# RX64M_RTC_Pilot register map
File version: 1.0
RX64M_RTC_Pilot peripheral registers generated from iodefine.h (pilot).
Registers are 8-bit, read-write, no defined reset value unless marked. A register's access mark holds for its fields unless they carry their own. Offsets are from the block's base; lines under a group give offsets from that group; [hi:lo] are bit positions; {n}, {i} and the like mark numbered series; 'fields as' and 'values as' point back to an identical list; <NAME> marks a mode.

## Memory map
0x0008C400 RTC size 0x7D

## RTC
Base 0x0008C400
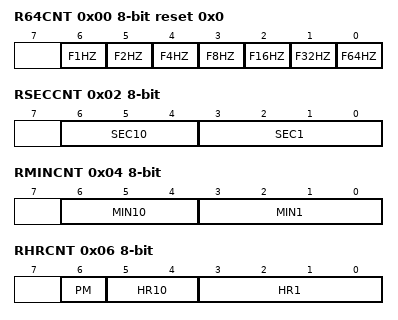
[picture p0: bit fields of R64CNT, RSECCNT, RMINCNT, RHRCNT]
0x00 R64CNT ro reset 0x0 (reset mask 0x80)
  [6] F1HZ, [5] F2HZ, [4] F4HZ, [3] F8HZ, [2] F16HZ, [1] F32HZ, [0] F64HZ
0x02 RSECCNT
  [6:4] SEC10, [3:0] SEC1
0x02 BCNT0 (alternate view of RSECCNT)
  [7:0] BCNT
0x04 RMINCNT
  [6:4] MIN10, [3:0] MIN1
0x04 BCNT1 (alternate view of RMINCNT)
  [7:0] BCNT
0x06 RHRCNT
  [6] PM, [5:4] HR10, [3:0] HR1
0x06 BCNT2 (alternate view of RHRCNT)
  [7:0] BCNT
0x08 RWKCNT
  [2:0] DAYW
0x08 BCNT3 (alternate view of RWKCNT)
  [7:0] BCNT
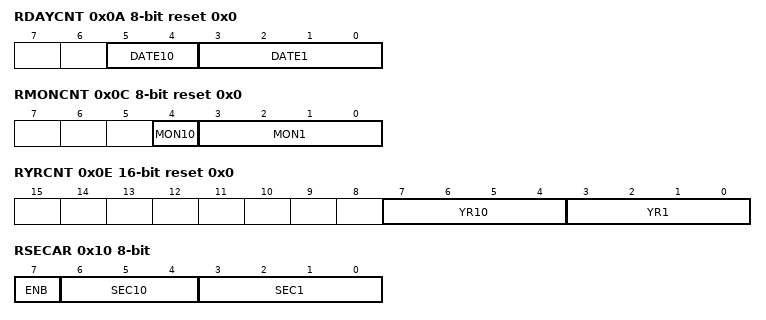
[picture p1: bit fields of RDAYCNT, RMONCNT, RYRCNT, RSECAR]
0x0A RDAYCNT reset 0x0 (reset mask 0xC0)
  [5:4] DATE10, [3:0] DATE1
0x0C RMONCNT reset 0x0 (reset mask 0xE0)
  [4] MON10, [3:0] MON1
0x0E RYRCNT 16-bit reset 0x0 (reset mask 0xFF00)
  [7:4] YR10, [3:0] YR1
0x10 RSECAR
  [7] ENB, [6:4] SEC10, [3:0] SEC1
0x10 BCNT0AR (alternate view of RSECAR)
  [7:0] BCNTAR
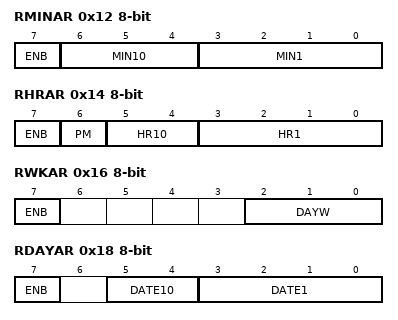
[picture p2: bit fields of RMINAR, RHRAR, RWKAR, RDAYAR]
0x12 RMINAR
  [7] ENB, [6:4] MIN10, [3:0] MIN1
0x12 BCNT1AR (alternate view of RMINAR)
  [7:0] BCNTAR
0x14 RHRAR
  [7] ENB, [6] PM, [5:4] HR10, [3:0] HR1
0x14 BCNT2AR (alternate view of RHRAR)
  [7:0] BCNTAR
0x16 RWKAR
  [7] ENB, [2:0] DAYW
0x16 BCNT3AR (alternate view of RWKAR)
  [7:0] BCNTAR
0x18 RDAYAR
  [7] ENB, [5:4] DATE10, [3:0] DATE1
0x18 BCNT0AER (alternate view of RDAYAR)
  [7:0] ENB
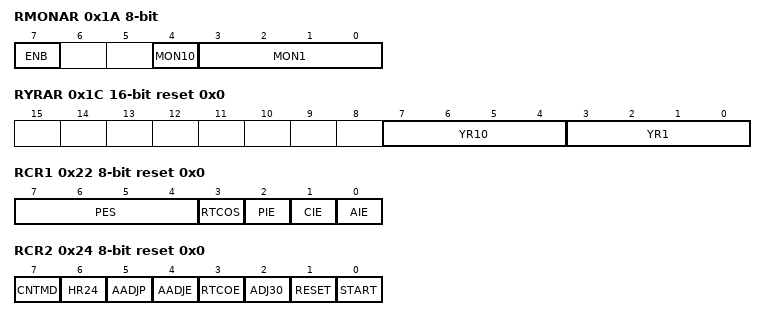
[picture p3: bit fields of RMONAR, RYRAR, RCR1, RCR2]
0x1A RMONAR
  [7] ENB, [4] MON10, [3:0] MON1
0x1A BCNT1AER (alternate view of RMONAR)
  [7:0] ENB
0x1C RYRAR 16-bit reset 0x0 (reset mask 0xFF00)
  [7:4] YR10, [3:0] YR1
0x1C BCNT2AER 16-bit reset 0x0 (reset mask 0xFF00) (alternate view of RYRAR)
  [7:0] ENB
0x1E RYRAREN
  [7] ENB
0x1E BCNT3AER (alternate view of RYRAREN)
  [7:0] ENB
0x22 RCR1 reset 0x0 (reset mask 0xA)
  [7:4] PES, [3] RTCOS, [2] PIE, [1] CIE, [0] AIE
0x24 RCR2 reset 0x0 (reset mask 0xE)
  [7] CNTMD, [6] HR24, [5] AADJP, [4] AADJE, [3] RTCOE, [2] ADJ30, [1] RESET, [0] START
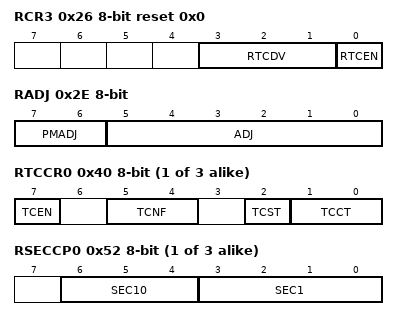
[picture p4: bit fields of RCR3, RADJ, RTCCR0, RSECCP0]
0x26 RCR3 reset 0x0 (reset mask 0xF0)
  [3:1] RTCDV, [0] RTCEN
0x28 RCR4 reset 0x0 (reset mask 0xFE)
  [0] RCKSEL
0x2A RFRH 16-bit reset 0x0 (reset mask 0xFFFE)
  [0] RFC
0x2C RFRL 16-bit
  [15:0] RFC
0x2E RADJ
  [7:6] PMADJ, [5:0] ADJ
{0x40+2i} RTCCR{i} (i=0..2)
  [7] TCEN, [5:4] TCNF, [2] TCST, [1:0] TCCT
{0x52+0x10*i} RSECCP{i} ro (i=0..2)
  [6:4] SEC10, [3:0] SEC1
{0x52+0x10*i} BCNT0CP{i} ro (alternate view of RSECCP{i}) (i=0..2)
  [7:0] BCNCP{i}
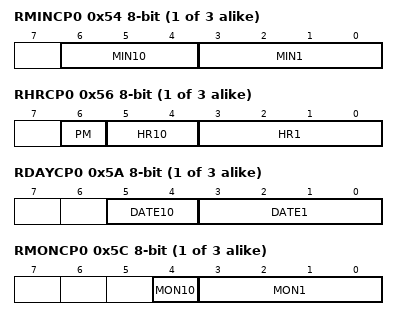
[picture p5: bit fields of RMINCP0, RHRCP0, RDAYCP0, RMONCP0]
{0x54+0x10*i} RMINCP{i} ro (i=0..2)
  [6:4] MIN10, [3:0] MIN1
{0x54+0x10*i} BCNT1CP{i} ro (alternate view of RMINCP{i}) (i=0..2)
  [7:0] BCNCP{i}
{0x56+0x10*i} RHRCP{i} ro (i=0..2)
  [6] PM, [5:4] HR10, [3:0] HR1
{0x56+0x10*i} BCNT2CP{i} ro (alternate view of RHRCP{i}) (i=0..2)
  [7:0] BCNCP{i}
{0x5A+0x10*i} RDAYCP{i} ro (i=0..2)
  [5:4] DATE10, [3:0] DATE1
{0x5A+0x10*i} BCNT3CP{i} ro (alternate view of RDAYCP{i}) (i=0..2)
  [7:0] BCNCP{i}
{0x5C+0x10*i} RMONCP{i} ro (i=0..2)
  [4] MON10, [3:0] MON1
